# I94100_v1_3 register map
File version: 1.0
Registers are 32-bit, read-write, reset 0x0 unless marked. A register's access mark holds for its fields unless they carry their own. Offsets are from the block's base; [hi:lo] are bit positions; {n}, {i} and the like mark numbered series.

## FMC — FMC Register Map
Base 0x4000C000
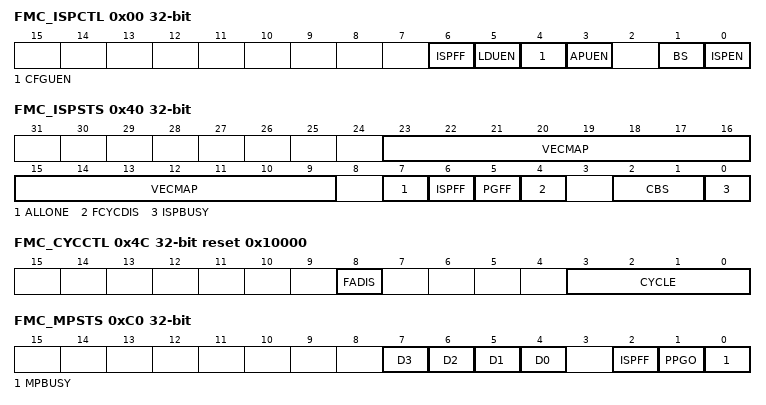
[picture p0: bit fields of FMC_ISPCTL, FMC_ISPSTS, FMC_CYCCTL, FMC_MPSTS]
0x00 FMC_ISPCTL — ISP Control Register
  [6] ISPFF — ISP Fail Flag (Write Protected). This bit is set by hardware when a triggered ISP meets any of the following conditions: (1) APROM writes to itself if APUEN is set to 0. (2) LDROM writes to itself if LDUEN is set to 0. (3) CONFIG is erased/programmed if CFGUEN is set to 0. (4) Destination address is illegal, such as over an available range. Note: This bit needs to be cleared by writing 1 to it.
  [5] LDUEN — LDROM Update Enable Bit (Write Protected). LDROM update enable bit.
    0=LDROM cannot be updated; 1=LDROM can be updated
  [4] CFGUEN — Config-Bits Update By ISP Enable Bit(Write Protected)
    0=ISP Disabled to update config-bits; 1=ISP Enabled to update config-bits
  [3] APUEN — APROM Update Enable Bit (Write Protected)
    0=APROM cannot be updated when the chip runs in APROM; 1=APROM can be updated when the chip runs in APROM
  [1] BS — Boot Select (Write Protected). Set/clear this bit to select next booting from LDROM/APROM, respectively. This bit also functions as chip booting status flag, which can be used to check where chip booted from. This bit is initiated with the inversed value of CBS in CONFIG0 after any reset is happened except CPU reset (RSTS_CPU is 1) or system reset (RSTS_SYS) is happened
    0=Boot from APROM; 1=Boot from LDROM
  [0] ISPEN — ISP Enable Bit (Write Protected). ISP function enable bit. Set this bit to enable ISP function.
    0=ISP function Disabled; 1=ISP function Enabled
0x04 FMC_ISPADDR — ISP Address Register
  [31:0] ISPADDR — ISP Address. The I94100 series is equipped with an embedded . ISPADDR[1:0] must be kept 00 for ISP 32-bit operation. ISPADDR[2:0] must be kept 000 for ISP 64-bit operation. ISPADDR[3:0] must be kept 0000 for ISP multi-word operation. For CRC32 Checksum Calculation command, this field is the flash starting address for checksum calculation, 4 Kbytes alignment is necessary for CRC32 checksum calculation. For FLASH 32-bit Program, ISP address needs word alignment (4-byte). For FLASH 64-bit Program, ISP address needs double word alignment (8-byte). For FLASH multi-word Program, ISP address needs four word alignment (16-byte).
0x08 FMC_ISPDAT — ISP Data Register
  [31:0] ISPDAT — ISP Data. Write data to this register before ISP program operation. Read data from this register after ISP read operation.
0x0C FMC_ISPCMD — ISP Command Register
  [6:0] CMD — ISP Command. ISP command table is shown below: The other commands are invalid.
    0=FLASH Read; 4=Read Unique ID; 8=Read Flash All-One Result; 11=Read Company ID; 12=Read Device ID; 13=Read Checksum; 33=FLASH 32-bit Program; 34=FLASH Page Erase. Erase page; 35=FLASH Bank Erase. Erase all pages of APROM; 37=FLASH Block Erase. Erase four pages alignment of APROM; 39=FLASH Multi-Word Program; 40=Run Flash All-One Verification; 45=Run Checksum Calculation; 46=Vector Remap; 64=FLASH 64-bit Read; 97=FLASH 64-bit Program
0x10 FMC_ISPTRG — ISP Trigger Register
  [0] ISPGO — ISP Start Trigger (Write Protected). Write 1 to start ISP operation and this bit will be cleared to 0 by hardware automatically when ISP operation is finished. Note: This bit is write protected. Refer to the SYS_REGLCTL register.
    0=ISP operation is finished; 1=ISP is progressed
0x14 FMC_DFBA ro reset not defined — Data Flash Base Address
  [31:0] DFBA — Data Flash Base Address. This register indicates Data Flash start address. It is a read only register. The Data Flash is shared with APROM. the content of this register is loaded from CONFIG1
0x40 FMC_ISPSTS ro (reset mask 0xFFFFFFF0) — ISP Status Register
  [23:9] VECMAP — Vector Page Mapping Address (Read Only). The current flash address space 0x0000_0000~0x0000_01FF is mapping to address {VECMAP[14:0], 9'h000} ~ {VECMAP[14:0], 9'h1FF}
  [7] ALLONE — Flash All-one Verification Flag. This bit is set by hardware if all of flash bits are 1, and clear if flash bits are not all 1 after "Run Flash All-One Verification" complete; this bit also can be clear by writing 1
    0=All of flash bits are 1 after "Run Flash All-One Verification" complete; 1=Flash bits are not all 1 after "Run Flash All-One Verification" complete
  [6] ISPFF — ISP Fail Flag (Read Only). This bit is set by hardware when a triggered ISP meets any of the following conditions: (1) APROM writes to itself if APUEN is set to 0. (2) LDROM writes to itself if LDUEN is set to 0. (3) CONFIG is erased/programmed if CFGUEN is set to 0. (4) Destination address is illegal, such as over an available range.
  [5] PGFF — Flash Program with Fast Verification Flag (Read Only). This bit is set if data is mismatched at ISP programming verification. This bit is cleared by performing ISP flash erase or ISP read CID operation
    0=Flash Program is success; 1=Flash Program has failed. Program data is different with data in the flash memory
  [4] FCYCDIS — Flash Access Cycle Auto-tuning Disabled Flag (Read Only). This bit is set if flash access cycle auto-tunning function is disabled. The auto-tunning function is disabled by FADIS(FMC_CYCCTL[8]) or HIRC clock is not ready.
    0=Flash access cycle auto-tuning is Enabled; 1=Flash access cyle auto-tuning is Disabled
  [2:1] CBS — Chip Boot Selection Mode (Read Only). This CBS field is just a copy of flash controller user configuration register CBS (CONFIG0 [7:6]). Note: The reset value of FMC_ISPSTS[3:0] is 1xx0b.
  [0] ISPBUSY — ISP Busy Flag (Read Only). Note: The reset value of FMC_ISPSTS[3:0] is 1xx0b.
    0=ISP operation is finished; 1=ISP is progressed
0x4C FMC_CYCCTL reset 0x10000 — Flash Access Cycle Control Register
  [8] FADIS — Flash Access Cycle Auto-tuning Disabled Control (Write Protect). Set this bit to disable flash access cycle auto-tuning function. Note: This bit is write protected. Refer to the SYS_REGLCTL register.
    0=Flash access cycle auto-tuning is enabled; 1=Flash access cycle auto-tuning is disabled
  [3:0] CYCLE — Flash Access Cycle Control (Write Protect). This register is updated automaticly by hardware while FCYCDIS (FMC_ISPSTS[4]) is 0, and updated by software while auto-tuning function disabled ( FADIS (FMC_CYCCTL[8]) is 1). The optimized HCLK working frequency range is >192 MHz. Note: This bit is write protected. Refer to the SYS_REGLCTL register.
    0=CPU access with zero wait cycle ; flash access cycle is 1;; 1=CPU access with one wait cycle if cache miss; flash access cylcle is 1;; 2=CPU access wtih two wait cycles if cahce miss; flash access cycle is 2;; 3=CPU access with three wait cycles if cache miss; flash access cylcle is 3;; 4=CPU access with four wait cycles if cahce miss; flash access cycle is 4;; 5=CPU access with five wait cycles if cache miss; flash access cylcle is 5;; 6=CPU access with six wait cycles if cahce miss; flash access cycle is 6;; 7=CPU access with seven wait cycles if cahce miss; flash access cycle is 7;; 8=CPU access with eight wait cycles if cache miss; flash access cylcle is 8;
0x80 FMC_MPDAT0 — ISP Multi-word Program Data0 Register
  [31:0] ISPDAT0 — ISP Data 0. This register is the first 32-bit data for 32-bit/64-bit/multi-word programming, and it is also the mirror of FMC_ISPDAT, both registers keep the same data.
0x84 FMC_MPDAT1 — ISP Multi-word Program Data1 Register
  [31:0] ISPDAT1 — ISP Data 1. This register is the second 32-bit data for 64-bit/multi-word programming.
0x88 FMC_MPDAT2 — ISP Multi-word Program Data2 Register
  [31:0] ISPDAT2 — ISP Data 2. This register is the third 32-bit data for multi-word programming.
0x8C FMC_MPDAT3 — ISP Multi-word Program Data3 Register
  [31:0] ISPDAT3 — ISP Data 3. This register is the fourth 32-bit data for multi-word programming.
0xC0 FMC_MPSTS ro — ISP Multi-word Program Status Register
  [n+4] D{n} (n=0..3) — ISP DATA {n} Flag (Read Only). This bit is set when FMC_MPDAT{n} is written and auto-clear to 0 when the FMC_MPDAT{n} data is programmed to flash complete.
    0=FMC_MPDAT{n} register is empty, or program to flash complete; 1=FMC_MPDAT{n} register has been written, and not program to flash complete
  [2] ISPFF — ISP Fail Flag (Read Only). This bit is the mirror of ISPFF (FMC_ISPCTL[6]), it needs to be cleared by writing 1 to FMC_ISPCTL[6] or FMC_ISPSTS[6]. This bit is set by hardware when a triggered ISP meets any of the following conditions: (1) APROM writes to itself if APUEN is set to 0. (2) LDROM writes to itself if LDUEN is set to 0. (3) CONFIG is erased/programmed if CFGUEN is set to 0. (4) Page Erase command at LOCK mode with ICE connection (5) Erase or Program command at brown-out detected (6) Destination address is illegal, such as over an available range. (7) Invalid ISP commands
  [1] PPGO — ISP Multi-program Status (Read Only)
    0=ISP multi-word program operation is not active; 1=ISP multi-word program operation is in progress
  [0] MPBUSY — ISP Multi-word Program Busy Flag (Read Only). Write 1 to start ISP Multi-Word program operation and this bit will be cleared to 0 by hardware automatically when ISP Multi-Word program operation is finished. This bit is the mirror of ISPGO(FMC_ISPTRG[0]).
    0=ISP Multi-Word program operation is finished; 1=ISP Multi-Word program operation is progressed
0xC4 FMC_MPADDR ro — ISP Multi-word Program Address Status Register
  [31:0] MPADDR — ISP Multi-word Program Address. MPADDR is the address of ISP multi-word program operation when ISPGO flag is 1. MPADDR will keep the final ISP address when ISP multi-word program is complete.
